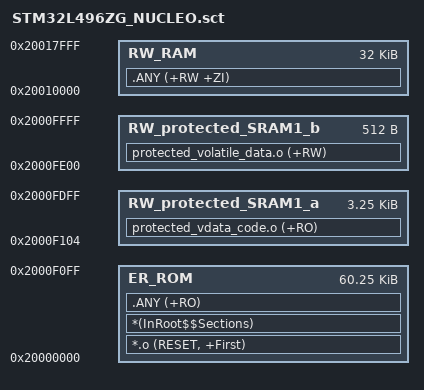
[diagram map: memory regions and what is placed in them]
; *************************************************************
; *** Scatter-Loading Description File generated by uVision ***
; *************************************************************

LR_ROM 0x20000000 0x0000F100  {    ; load region size_region
  ER_ROM 0x20000000 0x0000F100  {  ; load address = execution address
   *.o (RESET, +First)
   *(InRoot$$Sections)
   .ANY (+RO)
  }
  RW_RAM 0x20010000 0x00008000  {  ; RW data
   .ANY (+RW +ZI)
  }
; /****************************************************************************/
; /*                                                                          */
; /*     SRAM1_a: used to locate executable code in volatile data segment     */
; /*                  protected non-volatile data segment                     */
; /*                                                                          */
; /****************************************************************************/
RW_protected_SRAM1_a 0x2000F104 0x0000CFC {    
	protected_vdata_code.o (+RO)
}
;/******************************************************************************/  
;/*         place volatile data in SRAM1 area (more specifically in            */
;/*             SRAM1_b sub-region) to be protected by FIREWALL                */
;/******************************************************************************/ 
RW_protected_SRAM1_b 0x2000FE00 0x0000200 { 
protected_volatile_data.o (+RW)    
}
}
